# STM32H747ZIY6@M4 register map
File version: 1.0
Registers are 32-bit, access not given, reset 0x0 unless marked. A register's access mark holds for its fields unless they carry their own. Offsets are from the block's base; [hi:lo] are bit positions.

## LPTIM1
Base 0x40002400
Same registers: LPTIM2 0x58002400, LPTIM3 0x58002800, LPTIM4 0x58002C00, LPTIM5 0x58003000
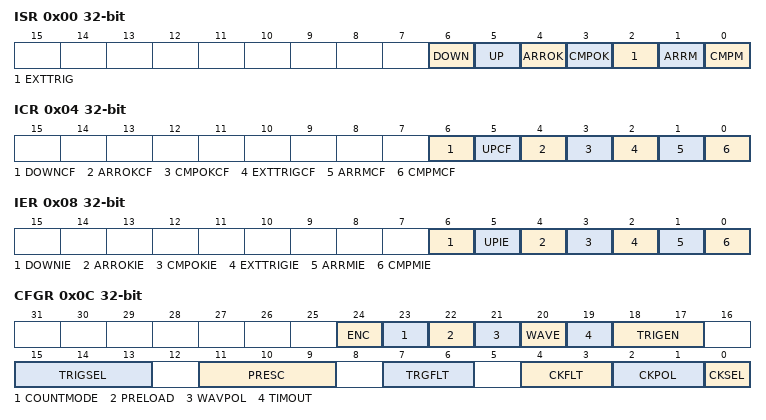
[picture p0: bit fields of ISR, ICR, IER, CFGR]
0x00 ISR
  [6] DOWN, [5] UP, [4] ARROK, [3] CMPOK, [2] EXTTRIG, [1] ARRM, [0] CMPM
0x04 ICR
  [6] DOWNCF, [5] UPCF, [4] ARROKCF, [3] CMPOKCF, [2] EXTTRIGCF, [1] ARRMCF, [0] CMPMCF
0x08 IER
  [6] DOWNIE, [5] UPIE, [4] ARROKIE, [3] CMPOKIE, [2] EXTTRIGIE, [1] ARRMIE, [0] CMPMIE
0x0C CFGR
  [24] ENC, [23] COUNTMODE, [22] PRELOAD, [21] WAVPOL, [20] WAVE, [19] TIMOUT, [18:17] TRIGEN, [15:13] TRIGSEL, [11:9] PRESC, [7:6] TRGFLT, [4:3] CKFLT, [2:1] CKPOL, [0] CKSEL
0x10 CR
  [4] RSTARE, [3] COUNTRST, [2] CNTSTRT, [19:1] SNGSTRT, [0] ENABLE
0x14 CMP
  [15:0] CMP
0x18 ARR
  [15:0] ARR
0x1C CNT
  [15:0] CNT
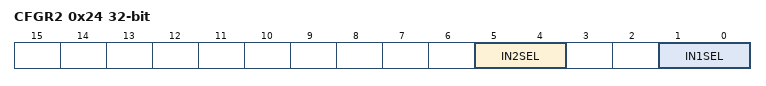
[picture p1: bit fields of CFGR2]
0x24 CFGR2
  [5:4] IN2SEL, [1:0] IN1SEL

## WWDG2
Base 0x40002C00
Same registers: WWDG1 0x50003000
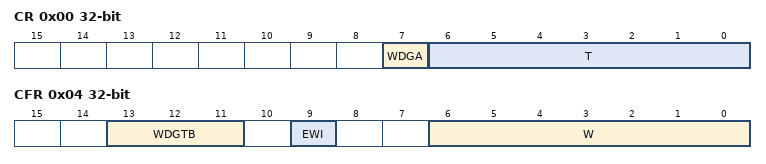
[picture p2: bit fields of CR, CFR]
0x00 CR
  [7] WDGA, [6:0] T
0x04 CFR
  [13:11] WDGTB, [9] EWI, [6:0] W
0x08 SR
  [0] EWIF

## SPI2
Base 0x40003800
Same registers: SPI3 0x40003C00, SPI1 0x40013000, SPI4 0x40013400, SPI5 0x40015000, SPI6 0x58001400
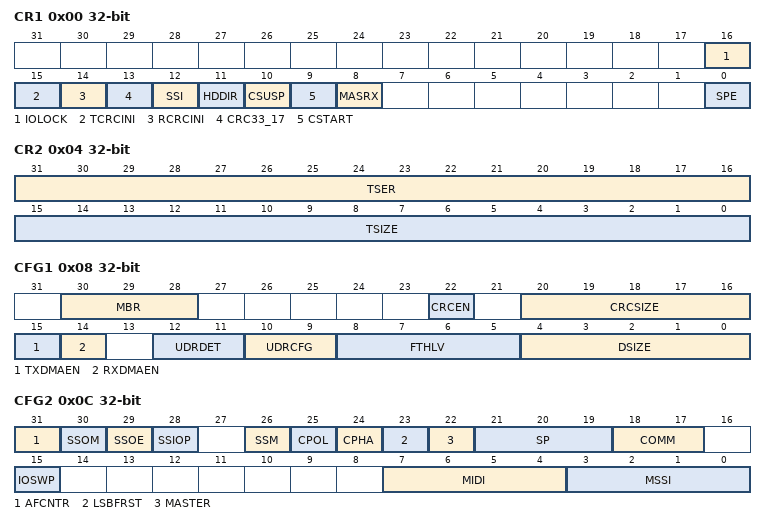
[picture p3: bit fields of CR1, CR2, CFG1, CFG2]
0x00 CR1
  [16] IOLOCK, [15] TCRCINI, [14] RCRCINI, [13] CRC33_17, [12] SSI, [11] HDDIR, [10] CSUSP, [9] CSTART, [8] MASRX, [0] SPE
0x04 CR2
  [31:16] TSER, [15:0] TSIZE
0x08 CFG1
  [30:28] MBR, [22] CRCEN, [20:16] CRCSIZE, [15] TXDMAEN, [14] RXDMAEN, [12:11] UDRDET, [10:9] UDRCFG, [8:5] FTHLV, [4:0] DSIZE
0x0C CFG2
  [31] AFCNTR, [30] SSOM, [29] SSOE, [28] SSIOP, [26] SSM, [25] CPOL, [24] CPHA, [23] LSBFRST, [22] MASTER, [21:19] SP, [18:17] COMM, [15] IOSWP, [7:4] MIDI, [3:0] MSSI
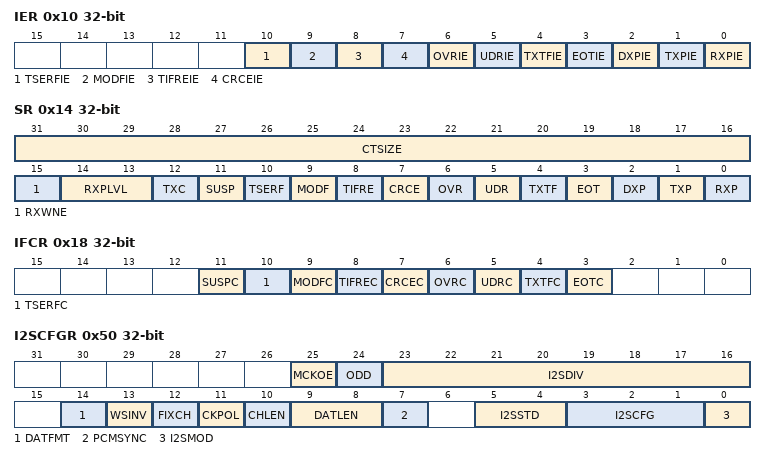
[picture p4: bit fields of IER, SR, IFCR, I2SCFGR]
0x10 IER
  [10] TSERFIE, [9] MODFIE, [8] TIFREIE, [7] CRCEIE, [6] OVRIE, [5] UDRIE, [4] TXTFIE, [3] EOTIE, [2] DXPIE, [1] TXPIE, [0] RXPIE
0x14 SR
  [31:16] CTSIZE, [15] RXWNE, [14:13] RXPLVL, [12] TXC, [11] SUSP, [10] TSERF, [9] MODF, [8] TIFRE, [7] CRCE, [6] OVR, [5] UDR, [4] TXTF, [3] EOT, [2] DXP, [1] TXP, [0] RXP
0x18 IFCR
  [11] SUSPC, [10] TSERFC, [9] MODFC, [8] TIFREC, [7] CRCEC, [6] OVRC, [5] UDRC, [4] TXTFC, [3] EOTC
0x20 TXDR
0x30 RXDR
0x40 CRCPOLY
0x44 TXCRC
0x48 RXCRC
0x4C UDRDR
0x50 I2SCFGR
  [25] MCKOE, [24] ODD, [23:16] I2SDIV, [14] DATFMT, [13] WSINV, [12] FIXCH, [11] CKPOL, [10] CHLEN, [9:8] DATLEN, [7] PCMSYNC, [5:4] I2SSTD, [3:1] I2SCFG, [0] I2SMOD

## SPDIFRX
Base 0x40004000
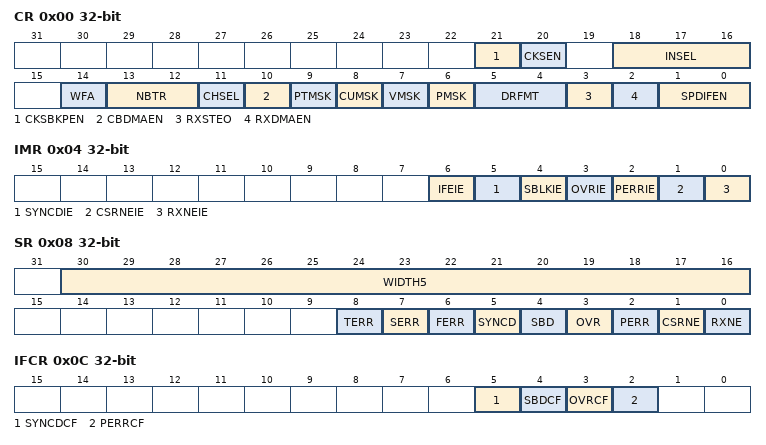
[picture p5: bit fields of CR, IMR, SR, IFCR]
0x00 CR
  [21] CKSBKPEN, [20] CKSEN, [18:16] INSEL, [14] WFA, [13:12] NBTR, [11] CHSEL, [10] CBDMAEN, [9] PTMSK, [8] CUMSK, [7] VMSK, [6] PMSK, [5:4] DRFMT, [3] RXSTEO, [2] RXDMAEN, [1:0] SPDIFEN
0x04 IMR
  [6] IFEIE, [5] SYNCDIE, [4] SBLKIE, [3] OVRIE, [2] PERRIE, [1] CSRNEIE, [0] RXNEIE
0x08 SR
  [30:16] WIDTH5, [8] TERR, [7] SERR, [6] FERR, [5] SYNCD, [4] SBD, [3] OVR, [2] PERR, [1] CSRNE, [0] RXNE
0x0C IFCR
  [5] SYNCDCF, [4] SBDCF, [3] OVRCF, [2] PERRCF
0x10 DR
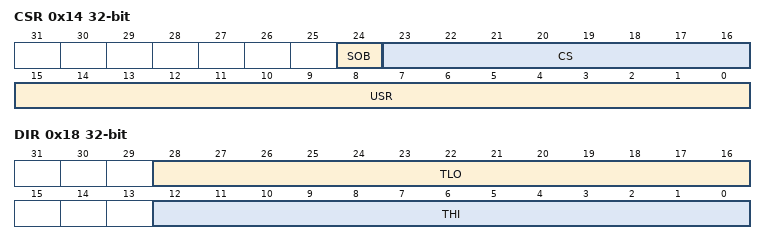
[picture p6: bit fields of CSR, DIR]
0x14 CSR
  [24] SOB, [23:16] CS, [15:0] USR
0x18 DIR
  [28:16] TLO, [12:0] THI

## USART2
Base 0x40004400
Same registers: USART3 0x40004800, UART4 0x40004C00, UART5 0x40005000, UART7 0x40007800, UART8 0x40007C00, USART1 0x40011000, USART6 0x40011400, LPUART1 0x58000C00
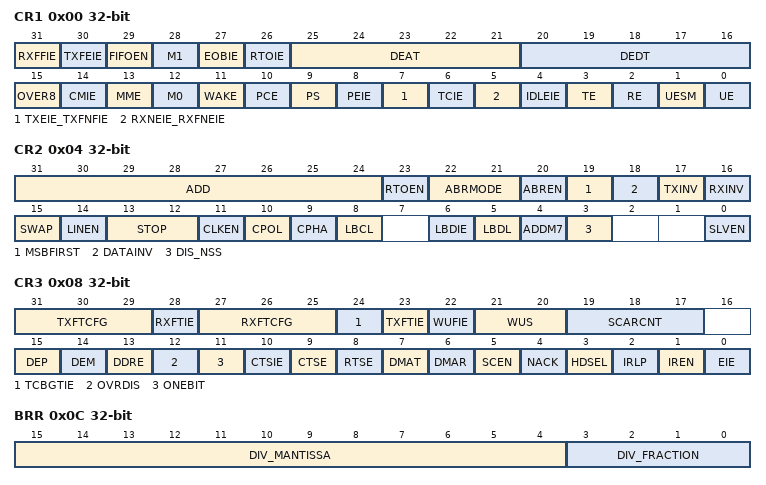
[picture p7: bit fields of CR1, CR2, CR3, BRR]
0x00 CR1
  [31] RXFFIE, [30] TXFEIE, [29] FIFOEN, [28] M1, [27] EOBIE, [26] RTOIE, [25:21] DEAT, [20:16] DEDT, [15] OVER8, [14] CMIE, [13] MME, [12] M0, [11] WAKE, [10] PCE, [9] PS, [8] PEIE, [7] TXEIE_TXFNFIE, [6] TCIE, [5] RXNEIE_RXFNEIE, [4] IDLEIE, [3] TE, [2] RE, [1] UESM, [0] UE
0x04 CR2
  [31:24] ADD, [23] RTOEN, [22:21] ABRMODE, [20] ABREN, [19] MSBFIRST, [18] DATAINV, [17] TXINV, [16] RXINV, [15] SWAP, [14] LINEN, [13:12] STOP, [11] CLKEN, [10] CPOL, [9] CPHA, [8] LBCL, [6] LBDIE, [5] LBDL, [4] ADDM7, [3] DIS_NSS, [0] SLVEN
0x08 CR3
  [31:29] TXFTCFG, [28] RXFTIE, [27:25] RXFTCFG, [24] TCBGTIE, [23] TXFTIE, [22] WUFIE, [21:20] WUS, [19:17] SCARCNT, [15] DEP, [14] DEM, [13] DDRE, [12] OVRDIS, [11] ONEBIT, [10] CTSIE, [9] CTSE, [8] RTSE, [7] DMAT, [6] DMAR, [5] SCEN, [4] NACK, [3] HDSEL, [2] IRLP, [1] IREN, [0] EIE
0x0C BRR
  [15:4] DIV_MANTISSA, [3:0] DIV_FRACTION
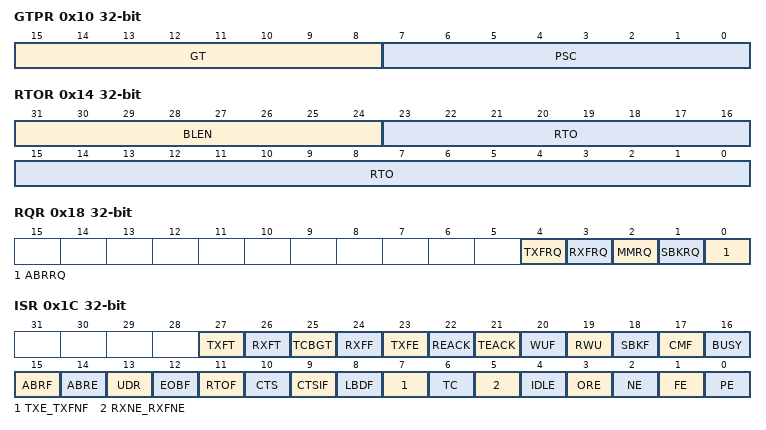
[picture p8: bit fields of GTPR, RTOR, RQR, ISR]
0x10 GTPR
  [15:8] GT, [7:0] PSC
0x14 RTOR
  [31:24] BLEN, [23:0] RTO
0x18 RQR
  [4] TXFRQ, [3] RXFRQ, [2] MMRQ, [1] SBKRQ, [0] ABRRQ
0x1C ISR
  [27] TXFT, [26] RXFT, [25] TCBGT, [24] RXFF, [23] TXFE, [22] REACK, [21] TEACK, [20] WUF, [19] RWU, [18] SBKF, [17] CMF, [16] BUSY, [15] ABRF, [14] ABRE, [13] UDR, [12] EOBF, [11] RTOF, [10] CTS, [9] CTSIF, [8] LBDF, [7] TXE_TXFNF, [6] TC, [5] RXNE_RXFNE, [4] IDLE, [3] ORE, [2] NE, [1] FE, [0] PE
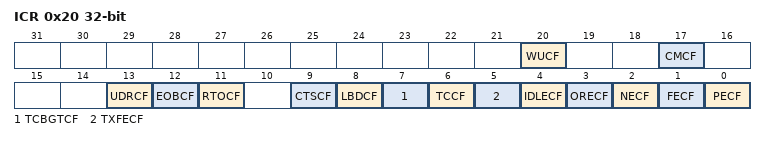
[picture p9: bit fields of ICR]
0x20 ICR
  [20] WUCF, [17] CMCF, [13] UDRCF, [12] EOBCF, [11] RTOCF, [9] CTSCF, [8] LBDCF, [7] TCBGTCF, [6] TCCF, [5] TXFECF, [4] IDLECF, [3] ORECF, [2] NECF, [1] FECF, [0] PECF
0x24 RDR
  [8:0] RDR
0x28 TDR
  [8:0] TDR
0x2C PRESC
  [3:0] PRESCALER
